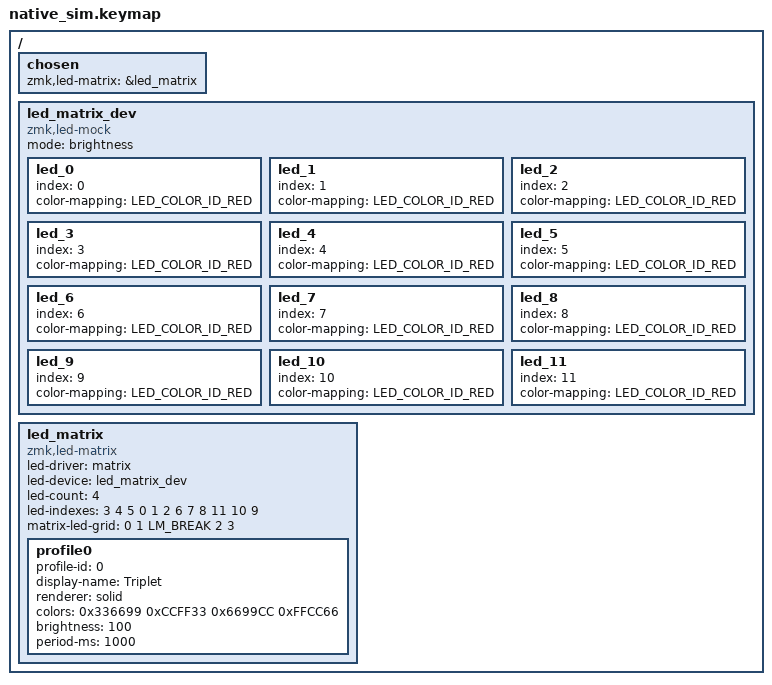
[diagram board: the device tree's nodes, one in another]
#include "../behavior_keymap.dtsi"

/ {
    chosen {
        zmk,led-matrix = &led_matrix;
    };

    led_matrix_dev: led_matrix_dev {
        compatible = "zmk,led-mock";
        mode = "brightness";

        led_0 { index = <0>; color-mapping = <LED_COLOR_ID_RED>; };
        led_1 { index = <1>; color-mapping = <LED_COLOR_ID_RED>; };
        led_2 { index = <2>; color-mapping = <LED_COLOR_ID_RED>; };
        led_3 { index = <3>; color-mapping = <LED_COLOR_ID_RED>; };
        led_4 { index = <4>; color-mapping = <LED_COLOR_ID_RED>; };
        led_5 { index = <5>; color-mapping = <LED_COLOR_ID_RED>; };
        led_6 { index = <6>; color-mapping = <LED_COLOR_ID_RED>; };
        led_7 { index = <7>; color-mapping = <LED_COLOR_ID_RED>; };
        led_8 { index = <8>; color-mapping = <LED_COLOR_ID_RED>; };
        led_9 { index = <9>; color-mapping = <LED_COLOR_ID_RED>; };
        led_10 { index = <10>; color-mapping = <LED_COLOR_ID_RED>; };
        led_11 { index = <11>; color-mapping = <LED_COLOR_ID_RED>; };
    };

    led_matrix: led_matrix {
        compatible = "zmk,led-matrix";
        led-driver = "matrix";
        led-device = <&led_matrix_dev>;
        led-count = <4>;
        led-indexes = <
            3 4 5
            0 1 2
            6 7 8
            11 10 9
        >;
        matrix-led-grid = <
            0 1 LM_BREAK
            2 3
        >;

        profile0 {
            profile-id = <0>;
            display-name = "Triplet";
            renderer = "solid";
            colors = <0x336699 0xCCFF33 0x6699CC 0xFFCC66>;
            brightness = <100>;
            period-ms = <1000>;
        };
    };
};
